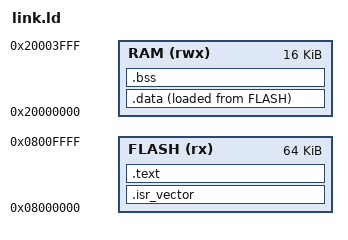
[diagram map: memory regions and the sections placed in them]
/* SPDX-License-Identifier: Apache-2.0 */
/* A small Cortex-M part: 64 KiB of flash at 0x08000000, 16 KiB of SRAM at
 * 0x20000000. The vector table is the first thing in flash. */
MEMORY
{
    FLASH (rx)  : ORIGIN = 0x08000000, LENGTH = 64K
    RAM   (rwx) : ORIGIN = 0x20000000, LENGTH = 16K
}

_estack = ORIGIN(RAM) + LENGTH(RAM);

SECTIONS
{
    .isr_vector : { KEEP(*(.isr_vector)) } > FLASH
    .text : { *(.text*) *(.rodata*) } > FLASH
    _sidata = LOADADDR(.data);
    .data : { _sdata = .; *(.data*) . = ALIGN(4); _edata = .; } > RAM AT > FLASH
    .bss (NOLOAD) : { _sbss = .; *(.bss*) *(COMMON) . = ALIGN(4); _ebss = .; } > RAM
    /DISCARD/ : { *(.ARM.exidx*) *(.comment) }
}
